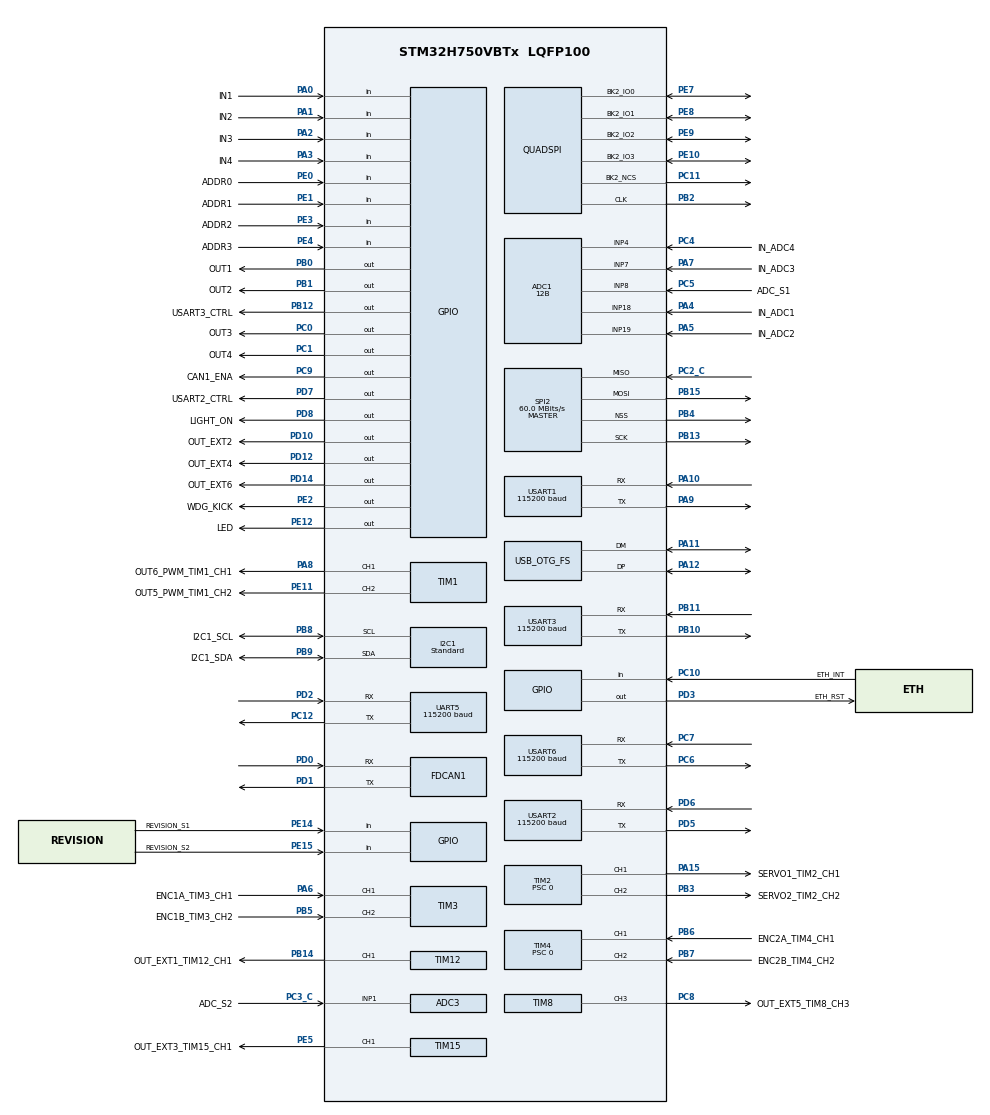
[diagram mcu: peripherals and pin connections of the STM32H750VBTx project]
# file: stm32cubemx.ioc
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ADC1.Channel-0\#ChannelRegularConversion=ADC_CHANNEL_4
ADC1.Channel-1\#ChannelRegularConversion=ADC_CHANNEL_7
ADC1.Channel-2\#ChannelRegularConversion=ADC_CHANNEL_8
ADC1.Channel-3\#ChannelRegularConversion=ADC_CHANNEL_18
ADC1.Channel-4\#ChannelRegularConversion=ADC_CHANNEL_19
ADC1.ClockPrescaler=ADC_CLOCK_ASYNC_DIV16
ADC1.ContinuousConvMode=ENABLE
ADC1.DMAContinuousRequests=DISABLE
ADC1.DiscontinuousConvMode=DISABLE
ADC1.EOCSelection=ADC_EOC_SEQ_CONV
ADC1.ExternalTrigConv=ADC_SOFTWARE_START
ADC1.ExternalTrigConvEdge=ADC_EXTERNALTRIGCONVEDGE_NONE
ADC1.NbrOfConversion=5
ADC1.Rank-0\#ChannelRegularConversion=1
ADC1.Rank-1\#ChannelRegularConversion=2
ADC1.Rank-2\#ChannelRegularConversion=3
ADC1.Rank-3\#ChannelRegularConversion=4
ADC1.Rank-4\#ChannelRegularConversion=5
ADC1.Resolution=ADC_RESOLUTION_12B
ADC1.master=1
ADC3.Channel-0\#ChannelRegularConversion=ADC_CHANNEL_1
ADC3.ClockPrescaler=ADC_CLOCK_ASYNC_DIV16
ADC3.NbrOfConversionFlag=1
ADC3.OffsetNumber-0\#ChannelRegularConversion=ADC_OFFSET_NONE
ADC3.Rank-0\#ChannelRegularConversion=1
ADC3.SamplingTime-0\#ChannelRegularConversion=ADC_SAMPLETIME_1CYCLE_5
CORTEX_M7.CPU_DCache=Enabled
CORTEX_M7.CPU_ICache=Enabled
FDCAN1.AutoRetransmission=ENABLE
FREERTOS.HEAP_NUMBER=1
FREERTOS.INCLUDE_eTaskGetState=0
FREERTOS.INCLUDE_pcTaskGetTaskName=0
FREERTOS.INCLUDE_uxTaskGetStackHighWaterMark=1
FREERTOS.INCLUDE_uxTaskGetStackHighWaterMark2=0
FREERTOS.INCLUDE_uxTaskPriorityGet=1
FREERTOS.INCLUDE_vTaskCleanUpResources=0
FREERTOS.INCLUDE_vTaskDelay=1
FREERTOS.INCLUDE_vTaskDelayUntil=1
FREERTOS.INCLUDE_vTaskDelete=0
FREERTOS.INCLUDE_vTaskPrioritySet=1
FREERTOS.INCLUDE_vTaskSuspend=1
FREERTOS.INCLUDE_xEventGroupSetBitFromISR=0
FREERTOS.INCLUDE_xQueueGetMutexHolder=0
FREERTOS.INCLUDE_xSemaphoreGetMutexHolder=0
FREERTOS.INCLUDE_xTaskAbortDelay=0
FREERTOS.INCLUDE_xTaskGetCurrentTaskHandle=0
FREERTOS.INCLUDE_xTaskGetHandle=0
FREERTOS.INCLUDE_xTaskResumeFromISR=1
FREERTOS.MEMORY_ALLOCATION=2
FREERTOS.Tasks01=defaultTask,0,128,StartDefaultTask,Default,NULL
FREERTOS.configCHECK_FOR_STACK_OVERFLOW=0
FREERTOS.configENABLE_BACKWARD_COMPATIBILITY=1
FREERTOS.configENABLE_FPU=0
FREERTOS.configGENERATE_RUN_TIME_STATS=0
FREERTOS.configIDLE_SHOULD_YIELD=1
FREERTOS.configLIBRARY_LOWEST_INTERRUPT_PRIORITY=15
FREERTOS.configLIBRARY_MAX_SYSCALL_INTERRUPT_PRIORITY=5
FREERTOS.configMAX_CO_ROUTINE_PRIORITIES=2
FREERTOS.configMAX_PRIORITIES=7
FREERTOS.configMAX_TASK_NAME_LEN=16
FREERTOS.configMINIMAL_STACK_SIZE=128
FREERTOS.configQUEUE_REGISTRY_SIZE=8
FREERTOS.configRECORD_STACK_HIGH_ADDRESS=0
FREERTOS.configTICK_RATE_HZ=1000
FREERTOS.configTOTAL_HEAP_SIZE=32768
FREERTOS.configUSE_APPLICATION_TASK_TAG=0
FREERTOS.configUSE_COUNTING_SEMAPHORES=0
FREERTOS.configUSE_CO_ROUTINES=0
FREERTOS.configUSE_DAEMON_TASK_STARTUP_HOOK=0
FREERTOS.configUSE_IDLE_HOOK=0
FREERTOS.configUSE_MALLOC_FAILED_HOOK=0
FREERTOS.configUSE_MUTEXES=1
FREERTOS.configUSE_NEWLIB_REENTRANT=0
FREERTOS.configUSE_POSIX_ERRNO=0
FREERTOS.configUSE_PREEMPTION=1
FREERTOS.configUSE_RECURSIVE_MUTEXES=0
FREERTOS.configUSE_STATS_FORMATTING_FUNCTIONS=0
FREERTOS.configUSE_TASK_NOTIFICATIONS=1
FREERTOS.configUSE_TICKLESS_IDLE=0
FREERTOS.configUSE_TICK_HOOK=0
FREERTOS.configUSE_TIMERS=0
FREERTOS.configUSE_TRACE_FACILITY=0
FREERTOS.copyHeapFile=1
I2C1.AddressingMode=I2C_ADDRESSINGMODE_7BIT
I2C1.Analog_Filter=I2C_ANALOGFILTER_ENABLE
I2C1.DualAddressMode=I2C_DUALADDRESS_DISABLE
I2C1.GeneralCallMode=I2C_GENERALCALL_DISABLE
I2C1.I2C_Coeff_DF=0
I2C1.I2C_Speed_Mode=I2C_Standard
I2C1.NoStretchMode=I2C_NOSTRETCH_DISABLE
I2C1.OwnAddress=0
I2C1.Speed=100
I2C1.Timing=0x307075B1
IWDG1.Prescaler=IWDG_PRESCALER_4
IWDG1.Reload=4095
Mcu.Family=STM32H7
Mcu.Name=STM32H750VBTx
Mcu.Package=LQFP100
Mdma.MDMA_Channel0.QUADSPI_FIFO_TH.0.BlockCount=0
Mdma.MDMA_Channel0.QUADSPI_FIFO_TH.0.BlockDataLength=0
Mdma.MDMA_Channel0.QUADSPI_FIFO_TH.0.BufferTransferLength=1
Mdma.MDMA_Channel0.QUADSPI_FIFO_TH.0.CircularMode=MDMA_LINEAR_LIST
Mdma.MDMA_Channel0.QUADSPI_FIFO_TH.0.DataAlignment=MDMA_DATAALIGN_PACKENABLE
Mdma.MDMA_Channel0.QUADSPI_FIFO_TH.0.DestBlockAddressOffset=0
Mdma.MDMA_Channel0.QUADSPI_FIFO_TH.0.DestBurst=MDMA_DEST_BURST_SINGLE
Mdma.MDMA_Channel0.QUADSPI_FIFO_TH.0.DestDataSize=MDMA_DEST_DATASIZE_BYTE
Mdma.MDMA_Channel0.QUADSPI_FIFO_TH.0.DestinationInc=MDMA_DEST_INC_DISABLE
Mdma.MDMA_Channel0.QUADSPI_FIFO_TH.0.DstAddress=0
Mdma.MDMA_Channel0.QUADSPI_FIFO_TH.0.Endianness=MDMA_LITTLE_ENDIANNESS_PRESERVE
Mdma.MDMA_Channel0.QUADSPI_FIFO_TH.0.Instance=MDMA_Channel0
Mdma.MDMA_Channel0.QUADSPI_FIFO_TH.0.MaskAddress=0
Mdma.MDMA_Channel0.QUADSPI_FIFO_TH.0.MaskData=0
Mdma.MDMA_Channel0.QUADSPI_FIFO_TH.0.Priority=MDMA_PRIORITY_HIGH
Mdma.MDMA_Channel0.QUADSPI_FIFO_TH.0.Rank=First
Mdma.MDMA_Channel0.QUADSPI_FIFO_TH.0.SourceBlockAddressOffset=0
Mdma.MDMA_Channel0.QUADSPI_FIFO_TH.0.SourceBurst=MDMA_SOURCE_BURST_SINGLE
Mdma.MDMA_Channel0.QUADSPI_FIFO_TH.0.SourceDataSize=MDMA_SRC_DATASIZE_BYTE
Mdma.MDMA_Channel0.QUADSPI_FIFO_TH.0.SourceInc=MDMA_SRC_INC_WORD
Mdma.MDMA_Channel0.QUADSPI_FIFO_TH.0.SrcAddress=0
Mdma.MDMA_Channel0.QUADSPI_FIFO_TH.0.TransferTriggerMode=MDMA_BUFFER_TRANSFER
Mdma.MDMA_Channel0.Request0=QUADSPI_FIFO_TH
Mdma.MDMA_Channel0.RequestsNb=1
Mdma.RequestSet0=MDMA_Channel0
Mdma.RequestSetsNb=1
NVIC.OTG_FS_IRQn=true\:5\:0\:false\:false\:true\:true\:false\:true
NVIC.PriorityGroup=NVIC_PRIORITYGROUP_4
NVIC.QUADSPI_IRQn=true\:5\:0\:false\:false\:true\:true\:true\:true
NVIC.TIM17_IRQn=true\:0\:0\:false\:false\:true\:false\:false\:true
NVIC.TimeBase=TIM17_IRQn
NVIC.TimeBaseIP=TIM17
PA0.GPIO_Label=IN1
PA0.Signal=GPIO_Input
PA1.GPIO_Label=IN2
PA1.Signal=GPIO_Input
PA10.Mode=Asynchronous
PA10.Signal=USART1_RX
PA11.Mode=Device_Only
PA11.Signal=USB_OTG_FS_DM
PA12.Mode=Device_Only
PA12.Signal=USB_OTG_FS_DP
PA13\ (JTMS/SWDIO).Mode=Serial_Wire
PA13\ (JTMS/SWDIO).Signal=DEBUG_JTMS-SWDIO
PA14\ (JTCK/SWCLK).Mode=Serial_Wire
PA14\ (JTCK/SWCLK).Signal=DEBUG_JTCK-SWCLK
PA15\ (JTDI).GPIO_Label=SERVO1_TIM2_CH1
PA15\ (JTDI).Signal=S_TIM2_CH1
PA2.GPIO_Label=IN3
PA2.Signal=GPIO_Input
PA3.GPIO_Label=IN4
PA3.Signal=GPIO_Input
PA4.GPIO_Label=IN_ADC1
PA4.Signal=ADCx_INP18
PA5.GPIO_Label=IN_ADC2
PA5.Signal=ADCx_INP19
PA6.GPIO_Label=ENC1A_TIM3_CH1
PA6.Signal=S_TIM3_CH1
PA7.GPIO_Label=IN_ADC3
PA7.Signal=ADCx_INP7
PA8.GPIO_Label=OUT6_PWM_TIM1_CH1
PA8.Signal=S_TIM1_CH1
PA9.Mode=Asynchronous
PA9.Signal=USART1_TX
PB0.GPIO_Label=OUT1
PB0.Signal=GPIO_Output
PB1.GPIO_Label=OUT2
PB1.Signal=GPIO_Output
PB10.Mode=Asynchronous
PB10.Signal=USART3_TX
PB11.Mode=Asynchronous
PB11.Signal=USART3_RX
PB12.GPIO_Label=USART3_CTRL
PB12.Signal=GPIO_Output
PB13.Mode=Full_Duplex_Master
PB13.Signal=SPI2_SCK
PB14.GPIO_Label=OUT_EXT1_TIM12_CH1
PB14.Signal=S_TIM12_CH1
PB15.Mode=Full_Duplex_Master
PB15.Signal=SPI2_MOSI
PB2.Mode=Single Bank 2
PB2.Signal=QUADSPI_CLK
PB3\ (JTDO/TRACESWO).GPIO_Label=SERVO2_TIM2_CH2
PB3\ (JTDO/TRACESWO).Signal=S_TIM2_CH2
PB4\ (NJTRST).Mode=NSS_Signal_Hard_Output
PB4\ (NJTRST).Signal=SPI2_NSS
PB5.GPIO_Label=ENC1B_TIM3_CH2
PB5.Signal=S_TIM3_CH2
PB6.GPIO_Label=ENC2A_TIM4_CH1
PB6.Signal=S_TIM4_CH1
PB7.GPIO_Label=ENC2B_TIM4_CH2
PB7.Signal=S_TIM4_CH2
PB8.GPIO_Label=I2C1_SCL
PB8.Mode=I2C
PB8.Signal=I2C1_SCL
PB9.GPIO_Label=I2C1_SDA
PB9.Mode=I2C
PB9.Signal=I2C1_SDA
PC0.GPIO_Label=OUT3
PC0.Signal=GPIO_Output
PC1.GPIO_Label=OUT4
PC1.Signal=GPIO_Output
PC10.GPIO_Label=ETH_INT
PC10.Signal=GPIO_Input
PC11.Mode=Single Bank 2
PC11.Signal=QUADSPI_BK2_NCS
PC12.Mode=Asynchronous
PC12.Signal=UART5_TX
PC2_C.Mode=Full_Duplex_Master
PC2_C.Signal=SPI2_MISO
PC3_C.GPIO_Label=ADC_S2
PC3_C.Mode=IN1-Single-Ended
PC3_C.Signal=ADC3_INP1
PC4.GPIO_Label=IN_ADC4
PC4.Signal=ADCx_INP4
PC5.GPIO_Label=ADC_S1
PC5.Signal=ADCx_INP8
PC6.Mode=Asynchronous
PC6.Signal=USART6_TX
PC7.Mode=Asynchronous
PC7.Signal=USART6_RX
PC8.GPIO_Label=OUT_EXT5_TIM8_CH3
PC8.Signal=S_TIM8_CH3
PC9.GPIO_Label=CAN1_ENA
PC9.Signal=GPIO_Output
PD0.Mode=FDCANMaster
PD0.Signal=FDCAN1_RX
PD1.Mode=FDCANMaster
PD1.Signal=FDCAN1_TX
PD10.GPIO_Label=OUT_EXT2
PD10.Signal=GPIO_Output
PD12.GPIO_Label=OUT_EXT4
PD12.Signal=GPIO_Output
PD14.GPIO_Label=OUT_EXT6
PD14.Signal=GPIO_Output
PD2.Mode=Asynchronous
PD2.Signal=UART5_RX
PD3.GPIO_Label=ETH_RST
PD3.Signal=GPIO_Output
PD5.Mode=Asynchronous
PD5.Signal=USART2_TX
PD6.Mode=Asynchronous
PD6.Signal=USART2_RX
PD7.GPIO_Label=USART2_CTRL
PD7.Signal=GPIO_Output
PD8.GPIO_Label=LIGHT_ON
PD8.Signal=GPIO_Output
PE0.GPIO_Label=ADDR0
PE0.GPIO_PuPd=GPIO_PULLDOWN
PE0.Signal=GPIO_Input
PE1.GPIO_Label=ADDR1
PE1.GPIO_PuPd=GPIO_PULLDOWN
PE1.Signal=GPIO_Input
PE10.Mode=Single Bank 2
PE10.Signal=QUADSPI_BK2_IO3
PE11.GPIO_Label=OUT5_PWM_TIM1_CH2
PE11.Signal=S_TIM1_CH2
PE12.GPIO_Label=LED
PE12.Signal=GPIO_Output
PE14.GPIO_Label=REVISION_S1
PE14.Signal=GPIO_Input
PE15.GPIO_Label=REVISION_S2
PE15.Signal=GPIO_Input
PE2.GPIO_Label=WDG_KICK
PE2.Signal=GPIO_Output
PE3.GPIO_Label=ADDR2
PE3.Signal=GPIO_Input
PE4.GPIO_Label=ADDR3
PE4.Signal=GPIO_Input
PE5.GPIO_Label=OUT_EXT3_TIM15_CH1
PE5.Signal=S_TIM15_CH1
PE7.Mode=Single Bank 2
PE7.Signal=QUADSPI_BK2_IO0
PE8.Mode=Single Bank 2
PE8.Signal=QUADSPI_BK2_IO1
PE9.Mode=Single Bank 2
PE9.Signal=QUADSPI_BK2_IO2
PH0-OSC_IN\ (PH0).Mode=HSE-External-Oscillator
PH0-OSC_IN\ (PH0).Signal=RCC_OSC_IN
PH1-OSC_OUT\ (PH1).Mode=HSE-External-Oscillator
PH1-OSC_OUT\ (PH1).Signal=RCC_OSC_OUT
ProjectManager.HeapSize=0x200
ProjectManager.StackSize=0x400
ProjectManager.TargetToolchain=Other Toolchains (GPDSC)
QUADSPI.ChipSelectHighTime=QSPI_CS_HIGH_TIME_1_CYCLE
QUADSPI.ClockPrescaler=4
QUADSPI.FlashSize=16
QUADSPI.SampleShifting=QSPI_SAMPLE_SHIFTING_HALFCYCLE
RCC.ADCFreq_Value=80000000
RCC.APB1Freq_Value=120000000
RCC.APB2Freq_Value=120000000
RCC.APB3Freq_Value=120000000
RCC.APB4Freq_Value=120000000
RCC.CortexFreq_Value=480000000
RCC.DATA_CACHE_ENABLE=1
RCC.DIVM1=1
RCC.DIVM2=1
RCC.DIVM3=1
RCC.DIVN1=120
RCC.DIVN2=20
RCC.DIVN3=24
RCC.DIVQ2=4
RCC.DIVQ3=4
RCC.DIVR3=4
RCC.FDCANCLockSelection=RCC_FDCANCLKSOURCE_PLL2
RCC.HCLKFreq_Value=120000000
RCC.HPRE=RCC_HCLK_DIV4
RCC.HSE_VALUE=8000000
RCC.INSTRUCTION_CACHE_ENABLE=1
RCC.PLL1_VCI_Range=RCC_PLL1VCIRANGE_3
RCC.PLL2FRACN=0
RCC.PLL2_VCI_Range-AdvancedSettings=RCC_PLL2VCIRANGE_0
RCC.PLL3FRACN=0
RCC.PLLFRACN=0
RCC.PREFETCH_ENABLE=1
RCC.PWREXT_OverDrive=PWREXT_OverDrive_DESACTIVATED
RCC.SYSCLKFreq_VALUE=480000000
RCC.SYSCLKSource=RCC_SYSCLKSOURCE_PLLCLK
RCC.USBCLockSelection=RCC_USBCLKSOURCE_PLL3
RCC.USBFreq_Value=48000000
SH.ADCx_INP18.0=ADC1_INP18,IN18-Single-Ended
SH.ADCx_INP19.0=ADC1_INP19,IN19-Single-Ended
SH.ADCx_INP4.0=ADC1_INP4,IN4-Single-Ended
SH.ADCx_INP7.0=ADC1_INP7,IN7-Single-Ended
SH.ADCx_INP8.0=ADC1_INP8,IN8-Single-Ended
SH.S_TIM12_CH1.0=TIM12_CH1,Output Compare1 CH1
SH.S_TIM15_CH1.0=TIM15_CH1,Output Compare1 CH1
SH.S_TIM1_CH1.0=TIM1_CH1,PWM Generation1 CH1
SH.S_TIM1_CH2.0=TIM1_CH2,PWM Generation2 CH2
SH.S_TIM2_CH1.0=TIM2_CH1,PWM Generation1 CH1
SH.S_TIM2_CH2.0=TIM2_CH2,PWM Generation2 CH2
SH.S_TIM3_CH1.0=TIM3_CH1,Encoder_Interface
SH.S_TIM3_CH2.0=TIM3_CH2,Encoder_Interface
SH.S_TIM4_CH1.0=TIM4_CH1,Encoder_Interface
SH.S_TIM4_CH2.0=TIM4_CH2,Encoder_Interface
SH.S_TIM8_CH3.0=TIM8_CH3,Output Compare3 CH3
SPI2.BaudRatePrescaler=SPI_BAUDRATEPRESCALER_8
SPI2.CalculateBaudRate=60.0 MBits/s
SPI2.DataSize=SPI_DATASIZE_8BIT
SPI2.Direction=SPI_DIRECTION_2LINES
SPI2.MasterSSIdleness=SPI_MASTER_SS_IDLENESS_01CYCLE
SPI2.Mode=SPI_MODE_MASTER
SPI2.VirtualNSS=VM_NSSHARD
SPI2.VirtualType=VM_MASTER
TIM1.Channel-PWM\ Generation1\ CH1=TIM_CHANNEL_1
TIM1.Channel-PWM\ Generation2\ CH2=TIM_CHANNEL_2
TIM12.Channel-Output\ Compare1\ CH1=TIM_CHANNEL_1
TIM15.Channel-Output\ Compare1\ CH1=TIM_CHANNEL_1
TIM2.AutoReloadPreload=TIM_AUTORELOAD_PRELOAD_DISABLE
TIM2.Channel-PWM\ Generation1\ CH1=TIM_CHANNEL_1
TIM2.Channel-PWM\ Generation2\ CH2=TIM_CHANNEL_2
TIM2.ClockDivision=TIM_CLOCKDIVISION_DIV1
TIM2.CounterMode=TIM_COUNTERMODE_UP
TIM2.OC1Preload_PWM=ENABLE
TIM2.OC2Preload_PWM=ENABLE
TIM2.OCFastMode_PWM-PWM\ Generation1\ CH1=TIM_OCFAST_DISABLE
TIM2.OCFastMode_PWM-PWM\ Generation2\ CH2=TIM_OCFAST_DISABLE
TIM2.OCMode_PWM-PWM\ Generation1\ CH1=TIM_OCMODE_PWM1
TIM2.OCMode_PWM-PWM\ Generation2\ CH2=TIM_OCMODE_PWM1
TIM2.OCPolarity_1=TIM_OCPOLARITY_HIGH
TIM2.OCPolarity_2=TIM_OCPOLARITY_HIGH
TIM2.Period=0
TIM2.Prescaler=0
TIM2.Pulse-PWM\ Generation1\ CH1=0
TIM2.Pulse-PWM\ Generation2\ CH2=0
TIM2.TIM_MasterOutputTrigger=TIM_TRGO_RESET
TIM2.TIM_MasterSlaveMode=TIM_MASTERSLAVEMODE_DISABLE
TIM3.EncoderMode=TIM_ENCODERMODE_TI12
TIM4.AutoReloadPreload=TIM_AUTORELOAD_PRELOAD_DISABLE
TIM4.ClockDivision=TIM_CLOCKDIVISION_DIV1
TIM4.CounterMode=TIM_COUNTERMODE_UP
TIM4.EncoderMode=TIM_ENCODERMODE_TI12
TIM4.IC1Filter=0
TIM4.IC1Polarity=TIM_ICPOLARITY_RISING
TIM4.IC1Prescaler=TIM_ICPSC_DIV1
TIM4.IC1Selection=TIM_ICSELECTION_DIRECTTI
TIM4.IC2Filter=0
TIM4.IC2Polarity=TIM_ICPOLARITY_RISING
TIM4.IC2Prescaler=TIM_ICPSC_DIV1
TIM4.IC2Selection=TIM_ICSELECTION_DIRECTTI
TIM4.Period=0
TIM4.Prescaler=0
TIM4.TIM_MasterOutputTrigger=TIM_TRGO_RESET
TIM4.TIM_MasterSlaveMode=TIM_MASTERSLAVEMODE_DISABLE
TIM8.Channel-Output\ Compare3\ CH3=TIM_CHANNEL_3
UART5.BaudRate=115200
UART5.Mode=MODE_TX_RX
UART5.OverSampling=UART_OVERSAMPLING_16
UART5.Parity=PARITY_NONE
UART5.StopBits=UART_STOPBITS_1
UART5.WordLength=WORDLENGTH_8B
USART1.BaudRate=115200
USART1.Mode=MODE_TX_RX
USART1.OverSampling=UART_OVERSAMPLING_16
USART1.Parity=PARITY_NONE
USART1.StopBits=STOPBITS_1
USART1.VirtualMode-Asynchronous=VM_ASYNC
USART1.WordLength=WORDLENGTH_8B
USART2.BaudRate=115200
USART2.Mode=MODE_TX_RX
USART2.OverSampling=UART_OVERSAMPLING_16
USART2.Parity=PARITY_NONE
USART2.StopBits=STOPBITS_1
USART2.VirtualMode-Asynchronous=VM_ASYNC
USART2.WordLength=WORDLENGTH_8B
USART3.BaudRate=115200
USART3.Mode=MODE_TX_RX
USART3.OverSampling=UART_OVERSAMPLING_16
USART3.Parity=PARITY_NONE
USART3.StopBits=STOPBITS_1
USART3.VirtualMode-Asynchronous=VM_ASYNC
USART3.WordLength=WORDLENGTH_8B
USART6.BaudRate=115200
USART6.Mode=MODE_TX_RX
USART6.OverSampling=UART_OVERSAMPLING_16
USART6.Parity=PARITY_NONE
USART6.StopBits=STOPBITS_1
USART6.VirtualMode=VM_ASYNC
USART6.WordLength=WORDLENGTH_8B
USB_DEVICE.APP_RX_DATA_SIZE-CDC_FS=2048
USB_DEVICE.APP_TX_DATA_SIZE-CDC_FS=2048
USB_DEVICE.CLASS_NAME_FS=CDC
USB_DEVICE.CONFIGURATION_STRING_CDC_FS=CDC Config
USB_DEVICE.INTERFACE_STRING_CDC_FS=CDC Interface
USB_DEVICE.LANGID_STRING-CDC_FS=1033
USB_DEVICE.MANUFACTURER_STRING-CDC_FS=STMicroelectronics
USB_DEVICE.PID_CDC_FS=22336
USB_DEVICE.PRODUCT_STRING_CDC_FS=STM32 Virtual ComPort
USB_DEVICE.USBD_DEBUG_LEVEL-CDC_FS=0
USB_DEVICE.USBD_MAX_NUM_CONFIGURATION-CDC_FS=1
USB_DEVICE.USBD_MAX_NUM_INTERFACES-CDC_FS=1
USB_DEVICE.USBD_MAX_STR_DESC_SIZ-CDC_FS=512
USB_DEVICE.USBD_SELF_POWERED-CDC_FS=1
USB_DEVICE.VID-CDC_FS=1155
USB_DEVICE.VirtualMode-CDC_FS=Cdc
USB_DEVICE.VirtualModeFS=Cdc_FS
USB_OTG_FS.Sof_enable=DISABLE
USB_OTG_FS.VirtualMode=Device_Only
USB_OTG_FS.low_power_enable=DISABLE
USB_OTG_FS.lpm_enable=DISABLE
USB_OTG_FS.vbus_sensing_enable=DISABLE
VP_FREERTOS_VS_CMSIS_V1.Mode=CMSIS_V1
VP_IWDG1_VS_IWDG.Mode=IWDG_Activate
VP_SYS_VS_tim17.Mode=TIM17
VP_TIM12_VS_ClockSourceINT.Mode=Internal
VP_TIM12_VS_OPM.Mode=OPM_bit
VP_TIM15_VS_ClockSourceINT.Mode=Internal
VP_TIM15_VS_OPM.Mode=OPM_bit
VP_TIM1_VS_ClockSourceINT.Mode=Internal
VP_TIM8_VS_ClockSourceINT.Mode=Internal
VP_TIM8_VS_OPM.Mode=OPM_bit
VP_USB_DEVICE_VS_USB_DEVICE_CDC_FS.Mode=CDC_FS
board=custom

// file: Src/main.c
/* USER CODE BEGIN Header */
/**
  ******************************************************************************
  * @file           : main.c
  * @brief          : Main program body
  ******************************************************************************
  * @attention
  *
  * <h2><center>&copy; Copyright (c) 2020 STMicroelectronics.
  * All rights reserved.</center></h2>
  *
  * This software component is licensed by ST under Ultimate Liberty license
  * SLA0044, the "License"; You may not use this file except in compliance with
  * the License. You may obtain a copy of the License at:
  *                             www.st.com/SLA0044
  *
  ******************************************************************************
  */
/* USER CODE END Header */

#include "main.h"
#include "cmsis_os.h"
#include "adc.h"
#include "fdcan.h"
#include "i2c.h"
#include "iwdg.h"
#include "mdma.h"
#include "quadspi.h"
#include "spi.h"
#include "tim.h"
#include "usart.h"
#include "usb_device.h"
#include "gpio.h"

void SystemClock_Config(void);
void MX_FREERTOS_Init(void);

int main(void)
{

  /* Enable I-Cache---------------------------------------------------------*/
  SCB_EnableICache();

  /* Enable D-Cache---------------------------------------------------------*/
  SCB_EnableDCache();

  /* MCU Configuration--------------------------------------------------------*/

  /* Reset of all peripherals, Initializes the Flash interface and the Systick. */
  HAL_Init();

  /* Configure the system clock */
  SystemClock_Config();

  /* Initialize all configured peripherals */
  MX_GPIO_Init();
  MX_MDMA_Init();
  MX_ADC1_Init();
  MX_UART5_Init();
  MX_USART1_UART_Init();
  MX_USART2_UART_Init();
  MX_I2C1_Init();
  MX_TIM12_Init();
  MX_TIM4_Init();
  MX_USART3_UART_Init();
  MX_TIM2_Init();
  MX_USART6_UART_Init();
  MX_IWDG1_Init();
  MX_TIM3_Init();
  MX_FDCAN1_Init();
  MX_QUADSPI_Init();
  MX_ADC3_Init();
  MX_TIM15_Init();
  MX_TIM1_Init();
  MX_TIM8_Init();
  MX_SPI2_Init();
  /* USER CODE BEGIN 2 */
  extern void system_main_init();

  system_main_init();

  /* USER CODE END 2 */

  /* Call init function for freertos objects (in freertos.c) */
  MX_FREERTOS_Init();
  /* Start scheduler */
  osKernelStart();

  /* We should never get here as control is now taken by the scheduler */
  /* Infinite loop */
  while (1)
  {

  }
}

void SystemClock_Config(void)
{
  RCC_OscInitTypeDef RCC_OscInitStruct = {0};
  RCC_ClkInitTypeDef RCC_ClkInitStruct = {0};
  RCC_PeriphCLKInitTypeDef PeriphClkInitStruct = {0};

  /** Supply configuration update enable
  */
  HAL_PWREx_ConfigSupply(PWR_LDO_SUPPLY);
  /** Configure the main internal regulator output voltage
  */
  __HAL_PWR_VOLTAGESCALING_CONFIG(PWR_REGULATOR_VOLTAGE_SCALE0);

  while(!__HAL_PWR_GET_FLAG(PWR_FLAG_VOSRDY)) {}
  /** Macro to configure the PLL clock source
  */
  __HAL_RCC_PLL_PLLSOURCE_CONFIG(RCC_PLLSOURCE_HSE);
  /** Initializes the CPU, AHB and APB busses clocks
  */
  RCC_OscInitStruct.OscillatorType = RCC_OSCILLATORTYPE_LSI|RCC_OSCILLATORTYPE_HSE;
  RCC_OscInitStruct.HSEState = RCC_HSE_ON;
  RCC_OscInitStruct.LSIState = RCC_LSI_ON;
  RCC_OscInitStruct.PLL.PLLState = RCC_PLL_ON;
  RCC_OscInitStruct.PLL.PLLSource = RCC_PLLSOURCE_HSE;
  RCC_OscInitStruct.PLL.PLLM = 1;
  RCC_OscInitStruct.PLL.PLLN = 120;
  RCC_OscInitStruct.PLL.PLLP = 2;
  RCC_OscInitStruct.PLL.PLLQ = 2;
  RCC_OscInitStruct.PLL.PLLR = 2;
  RCC_OscInitStruct.PLL.PLLRGE = RCC_PLL1VCIRANGE_3;
  RCC_OscInitStruct.PLL.PLLVCOSEL = RCC_PLL1VCOWIDE;
  RCC_OscInitStruct.PLL.PLLFRACN = 0;
  if (HAL_RCC_OscConfig(&RCC_OscInitStruct) != HAL_OK)
  {
    Error_Handler();
  }
  /** Initializes the CPU, AHB and APB busses clocks
  */
  RCC_ClkInitStruct.ClockType = RCC_CLOCKTYPE_HCLK|RCC_CLOCKTYPE_SYSCLK
                              |RCC_CLOCKTYPE_PCLK1|RCC_CLOCKTYPE_PCLK2
                              |RCC_CLOCKTYPE_D3PCLK1|RCC_CLOCKTYPE_D1PCLK1;
  RCC_ClkInitStruct.SYSCLKSource = RCC_SYSCLKSOURCE_PLLCLK;
  RCC_ClkInitStruct.SYSCLKDivider = RCC_SYSCLK_DIV1;
  RCC_ClkInitStruct.AHBCLKDivider = RCC_HCLK_DIV4;
  RCC_ClkInitStruct.APB3CLKDivider = RCC_APB3_DIV1;
  RCC_ClkInitStruct.APB1CLKDivider = RCC_APB1_DIV1;
  RCC_ClkInitStruct.APB2CLKDivider = RCC_APB2_DIV1;
  RCC_ClkInitStruct.APB4CLKDivider = RCC_APB4_DIV1;

  if (HAL_RCC_ClockConfig(&RCC_ClkInitStruct, FLASH_LATENCY_1) != HAL_OK)
  {
    Error_Handler();
  }
  PeriphClkInitStruct.PeriphClockSelection = RCC_PERIPHCLK_USART3|RCC_PERIPHCLK_USART2
                              |RCC_PERIPHCLK_USART6|RCC_PERIPHCLK_FDCAN
                              |RCC_PERIPHCLK_USART1|RCC_PERIPHCLK_UART5
                              |RCC_PERIPHCLK_SPI2|RCC_PERIPHCLK_ADC
                              |RCC_PERIPHCLK_I2C1|RCC_PERIPHCLK_USB
                              |RCC_PERIPHCLK_QSPI;
  PeriphClkInitStruct.PLL2.PLL2M = 1;
  PeriphClkInitStruct.PLL2.PLL2N = 20;
  PeriphClkInitStruct.PLL2.PLL2P = 2;
  PeriphClkInitStruct.PLL2.PLL2Q = 4;
  PeriphClkInitStruct.PLL2.PLL2R = 2;
  PeriphClkInitStruct.PLL2.PLL2RGE = RCC_PLL2VCIRANGE_3;
  PeriphClkInitStruct.PLL2.PLL2VCOSEL = RCC_PLL2VCOMEDIUM;
  PeriphClkInitStruct.PLL2.PLL2FRACN = 0;
  PeriphClkInitStruct.PLL3.PLL3M = 1;
  PeriphClkInitStruct.PLL3.PLL3N = 24;
  PeriphClkInitStruct.PLL3.PLL3P = 2;
  PeriphClkInitStruct.PLL3.PLL3Q = 4;
  PeriphClkInitStruct.PLL3.PLL3R = 4;
  PeriphClkInitStruct.PLL3.PLL3RGE = RCC_PLL3VCIRANGE_3;
  PeriphClkInitStruct.PLL3.PLL3VCOSEL = RCC_PLL3VCOWIDE;
  PeriphClkInitStruct.PLL3.PLL3FRACN = 0;
  PeriphClkInitStruct.QspiClockSelection = RCC_QSPICLKSOURCE_D1HCLK;
  PeriphClkInitStruct.Spi123ClockSelection = RCC_SPI123CLKSOURCE_PLL;
  PeriphClkInitStruct.FdcanClockSelection = RCC_FDCANCLKSOURCE_PLL2;
  PeriphClkInitStruct.Usart234578ClockSelection = RCC_USART234578CLKSOURCE_D2PCLK1;
  PeriphClkInitStruct.Usart16ClockSelection = RCC_USART16CLKSOURCE_D2PCLK2;
  PeriphClkInitStruct.I2c123ClockSelection = RCC_I2C123CLKSOURCE_D2PCLK1;
  PeriphClkInitStruct.UsbClockSelection = RCC_USBCLKSOURCE_PLL3;
  PeriphClkInitStruct.AdcClockSelection = RCC_ADCCLKSOURCE_PLL2;
  if (HAL_RCCEx_PeriphCLKConfig(&PeriphClkInitStruct) != HAL_OK)
  {
    Error_Handler();
  }
  /** Enable USB Voltage detector
  */
  HAL_PWREx_EnableUSBVoltageDetector();
}

 /**
  * @brief  Period elapsed callback in non blocking mode
  * @note   This function is called  when TIM17 interrupt took place, inside
  * HAL_TIM_IRQHandler(). It makes a direct call to HAL_IncTick() to increment
  * a global variable "uwTick" used as application time base.
  * @param  htim : TIM handle
  * @retval None
  */
void HAL_TIM_PeriodElapsedCallback(TIM_HandleTypeDef *htim)
{
  if (htim->Instance == TIM17) {
    HAL_IncTick();
  }
}

void Error_Handler(void)
{
}

/************************ (C) COPYRIGHT STMicroelectronics *****END OF FILE****/
